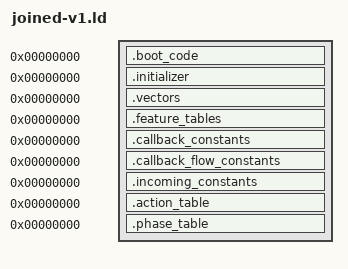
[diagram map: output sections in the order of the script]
OUTPUT_ARCH(riscv)
SECTIONS
{
 .boot_code 0 : SUBALIGN(2) { *(.boot_code)
  *(.text.tsl9_record_dispatch_provider_960e)
  *(.text.tsl9_state_controls_block_9616)
  *(.text.tsl9_state_controls_block_9620)
  *(.text.tsl9_state_controls_block_9652)
  *(.text.tsl9_state_controls_provider_ab02)
  *(.text.tsl9_record_dispatch_provider_ac0a)
  *(.text.tsl9_state_controls_block_ac10)
  *(.text.tsl9_state_controls_block_ac12)
  *(.text.tsl9_state_controls_block_ac14)
  *(.text.tsl9_state_controls_block_ac18)
  *(.text.tsl9_state_controls_block_ac24)
  *(.text.tsl9_state_controls_block_ac28)
  *(.text.tsl9_state_controls_block_ac2e)
  *(.text.tsl9_state_controls_block_ac30)
  *(.text.tsl9_state_controls_block_ac3e)
  *(.text.tsl9_state_controls_block_ac58)
  *(.text.tsl9_state_controls_block_ac6a)
  *(.text.tsl9_state_controls_block_ac70)
  *(.text.tsl9_record_dispatch_provider_d2ee)
  *(.text.tsl9_state_controls_block_d30a)
  *(.text.tsl9_feature_external_d332)
  *(.text.tsl9_state_controls_block_d346)
  *(.text.tsl9_state_controls_block_d35e)
  *(.text.tsl9_state_controls_block_d368)
  *(.text.tsl9_state_controls_block_d36c)
  *(.text.tsl9_state_controls_block_d376)
  *(.text.tsl9_state_controls_provider_10c7a)
  *(.text.tsl9_state_controls_block_10caa)
  *(.text.tsl9_state_controls_block_10cae)
  *(.text.tsl9_state_controls_block_10cb8)
  *(.text.tsl9_state_controls_block_10cca)
  *(.text.tsl9_state_controls_block_10ccc)
  *(.text.tsl9_state_controls_block_10cd6)
  *(.text.tsl9_registered_callbacks_provider_10d60)
  *(.text.tsl9_state_controls_block_10d74)
  *(.text.tsl9_state_controls_block_10d82)
  *(.text.tsl9_state_controls_block_10d88)
  *(.text.tsl9_state_controls_block_10d90)
  *(.text.tsl9_registered_callbacks_provider_10e82)
  *(.text.tsl9_state_controls_block_10eac)
  *(.text.tsl9_registered_callbacks_provider_10eb2)
  *(.text.tsl9_state_controls_block_10ed6)
  *(.text.tsl9_state_controls_block_10ef0)
  *(.text.tsl9_state_controls_block_10ef2)
  *(.text.tsl9_state_controls_block_10efa)
  *(.text.tsl9_state_controls_block_10f00)
  *(.text.tsl9_state_controls_block_10f10)
  *(.text.tsl9_state_controls_block_10f1e)
  *(.text.tsl9_state_controls_block_10f32)
  *(.text.tsl9_state_controls_block_10f34)
  *(.text.tsl9_state_controls_block_10f3c)
  *(.text.tsl9_state_controls_block_10f48)
  *(.text.tsl9_state_controls_block_10f62)
  *(.text.tsl9_state_controls_block_10f64)
  *(.text.tsl9_state_controls_block_10f6a)
  *(.text.tsl9_state_controls_block_10f6c)
  *(.text.tsl9_state_controls_block_10fac)
  *(.text.tsl9_state_controls_block_10fc0)
  *(.text.tsl9_state_controls_block_10fd8)
  *(.text.tsl9_state_controls_block_10fdc)
  *(.text.tsl9_state_controls_block_10fec)
  *(.text.tsl9_state_controls_block_11002)
  *(.text.tsl9_state_controls_block_11006)
  *(.text.tsl9_state_controls_block_1100c)
  *(.text.tsl9_state_controls_block_11034)
  *(.text.tsl9_state_controls_block_11052)
  *(.text.tsl9_state_controls_block_1105e)
  *(.text.tsl9_state_controls_block_11074)
  *(.text.tsl9_state_controls_block_11096)
  *(.text.tsl9_state_controls_block_110a8)
  *(.text.tsl9_state_controls_block_110aa)
  *(.text.tsl9_state_controls_block_110ba)
  *(.text.tsl9_state_controls_block_110c2)
  *(.text.tsl9_state_controls_block_110d2)
  *(.text.tsl9_state_controls_block_110ee)
  *(.text.tsl9_state_controls_block_110f6)
  *(.text.tsl9_state_controls_provider_167a6)
  *(.text.tsl9_state_controls_block_167c2)
  *(.text.tsl9_state_controls_block_167d0)
  *(.text.tsl9_state_controls_block_167d8)
  *(.text.tsl9_state_controls_block_167de)
  *(.text.tsl9_state_controls_block_167ee)
  *(.text.tsl9_state_controls_block_16808)
  *(.text.tsl9_state_controls_block_1680c)
  *(.text.tsl9_state_controls_block_16814)
  *(.text.tsl9_state_controls_block_1682e)
  *(.text.tsl9_state_controls_block_16832)
  *(.text.tsl9_state_controls_block_1683a)
  *(.text.tsl9_state_controls_block_16846)
 }
 .initializer 0 : SUBALIGN(4) { *(.initializer) }
 .vectors 0 : SUBALIGN(4) { *(.vectors) }
 .feature_tables 0 : SUBALIGN(4) { *(.feature_tables) }
 .callback_constants 0 : SUBALIGN(4) { *(.callback_constants) }
 .callback_flow_constants 0 : SUBALIGN(4) { *(.callback_flow_constants) }
 .incoming_constants 0 : SUBALIGN(4) { *(.incoming_constants) }
 .action_table 0 : SUBALIGN(4) { *(.action_table) }
 .phase_table 0 : SUBALIGN(4) { *(.phase_table) }
 /DISCARD/ : { *(.comment) *(.riscv.attributes) *(.llvm_addrsig) }
}
